AUTOSAR XML (schema 4-2-2)
package /Components
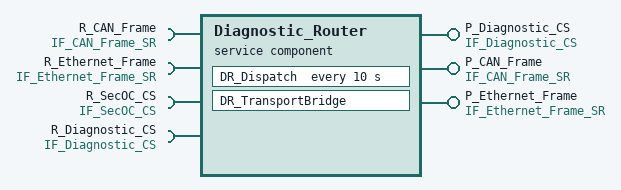
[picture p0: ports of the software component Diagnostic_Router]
  service sw component type Diagnostic_Router
    provide port P_Diagnostic_CS: provided-interface=IF_Diagnostic_CS
    provide port P_CAN_Frame: provided-interface=IF_CAN_Frame_SR
    provide port P_Ethernet_Frame: provided-interface=IF_Ethernet_Frame_SR
    4 x require port:
      R_CAN_Frame: required-interface=IF_CAN_Frame_SR
      R_Ethernet_Frame: required-interface=IF_Ethernet_Frame_SR
      R_SecOC_CS: required-interface=IF_SecOC_CS
      R_Diagnostic_CS: required-interface=IF_Diagnostic_CS
    behavior Diagnostic_Router_InternalBehavior
      data received event DR_RequestRx: start-on-event=DR_TransportBridge
      init event DR_InitEvent: start-on-event=DR_Dispatch
      timing event DR_DispatchSchedule: start-on-event=DR_Dispatch, period=10
      runnable DR_Dispatch: minimum-start-interval=10
        data-receive-point-by-values:
          access RX_CAN_Status_ForDispatch: accessed-variable=R_CAN_Frame.can_bus_status
        data-send-points:
          access TX_CAN_Frame_Response: accessed-variable=P_CAN_Frame.can_frame
          access TX_Ethernet_Frame_Response: accessed-variable=P_Ethernet_Frame.ethernet_frame
        sync call Diag_ReadById_Sync: operation=R_Diagnostic_CS.ReadDataByIdentifier_Op, timeout=80, called-from-within-exclusive-area=ExclusiveArea_Dispatch
        sync call Diag_RoutineControl_Sync: operation=R_Diagnostic_CS.RoutineControl_Op, timeout=100, called-from-within-exclusive-area=ExclusiveArea_Dispatch
      runnable DR_TransportBridge: minimum-start-interval=1, can-be-invoked-concurrently=true
        data-receive-point-by-values:
          access RX_CAN_Frame: accessed-variable=R_CAN_Frame.can_frame
          access RX_Ethernet_Frame: accessed-variable=R_Ethernet_Frame.ethernet_frame
        data-send-points:
          access TX_CAN_Frame_Bridge: accessed-variable=P_CAN_Frame.can_frame
          access TX_Ethernet_Frame_Bridge: accessed-variable=P_Ethernet_Frame.ethernet_frame
        async call SecOC_Verify_Async: operation=R_SecOC_CS.Verify_Auth_Tag_Op, timeout=5
